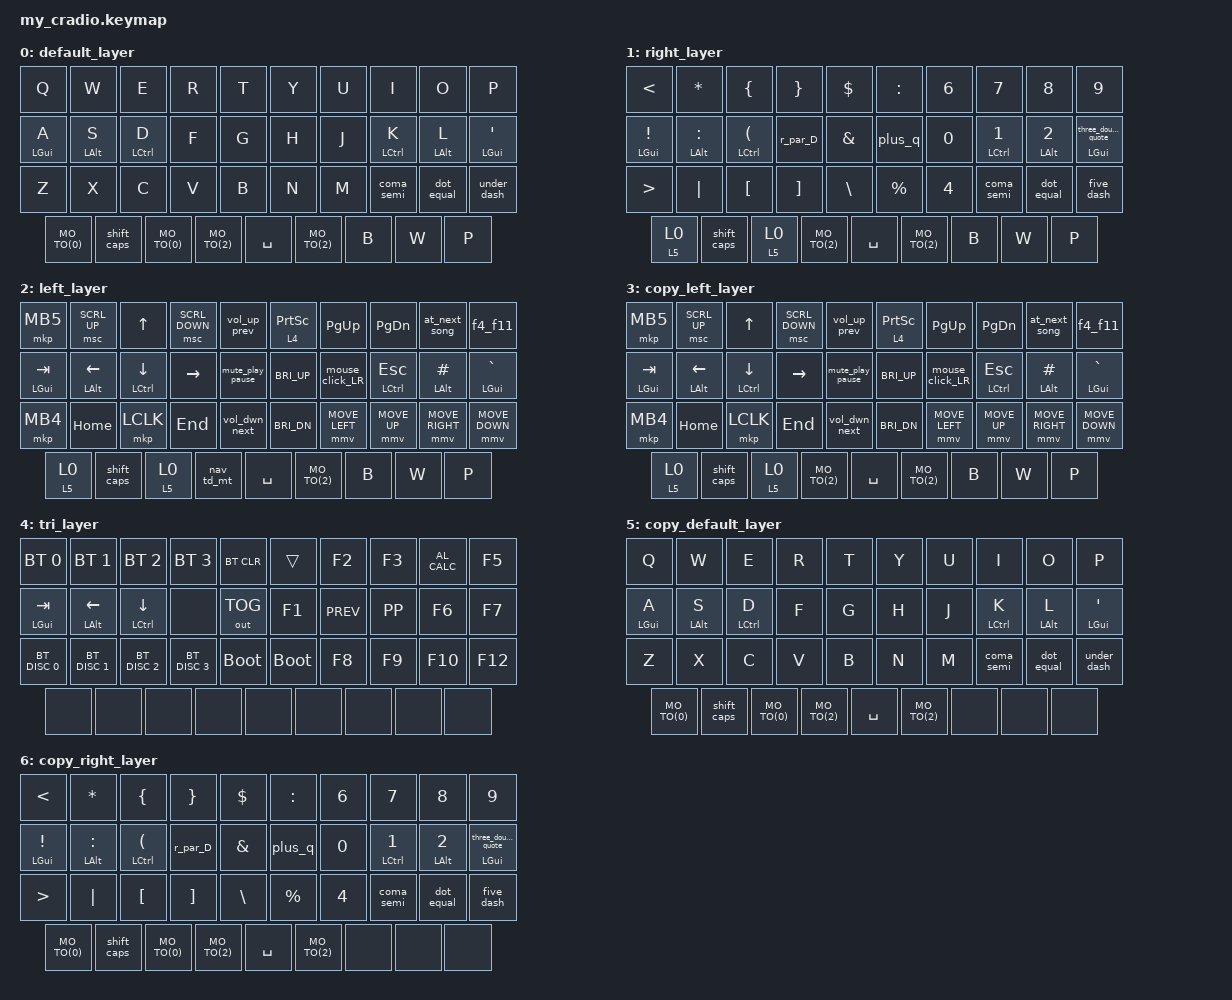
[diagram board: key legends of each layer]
// Copyright (c) 2022 The ZMK Contributors
// SPDX-License-Identifier: MIT

#define ZMK_POINTING_DEFAULT_MOVE_VAL 1500  // default: 600
#define ZMK_POINTING_DEFAULT_SCRL_VAL 200    // default: 10

#include <behaviors.dtsi>
#include <input/processors.dtsi>
#include <zephyr/dt-bindings/input/input-event-codes.h>
#include <dt-bindings/zmk/keys.h>
#include <dt-bindings/zmk/bt.h>
//#include <dt-bindings/zmk/mouse.h>
#include <dt-bindings/zmk/outputs.h>
#include <dt-bindings/zmk/pointing.h>


#define MO_TO(layer) &mo_to layer layer   // Macro to apply momentary-layer-on-hold/toggle-layer-on-tap to a specific layer

&mmv {
  acceleration-exponent = <1>;          // 1
  time-to-max-speed-ms = <700>;         // 300
  delay-ms = <0>;                       // 0
};

&msc {
  acceleration-exponent = <0>;          // 0
  time-to-max-speed-ms = <0>;         // 300
  delay-ms = <0>;                       // 0
};

&mmv_input_listener {
  fast {
    layers = <3>;
    input-processors = <&zip_xy_scaler 7 2>;
  };
};

&msc_input_listener {
  fast {
    layers = <3>;
    input-processors = <&zip_scroll_scaler 7 1>;
  };
};

/ {
    macros {
        fast_scrl_up: fast_scrl_up {
            compatible = "zmk,behavior-macro";
            #binding-cells = <0>;
            wait-ms = <0>;
            tap-ms = <0>;
            bindings
                = <&macro_press &mo 3>
                , <&macro_press &msc SCRL_UP>
                , <&macro_pause_for_release>
                , <&macro_release &msc SCRL_UP>
                , <&macro_release &mo 3>;
        };
        
        fast_scrl_dn: fast_scrl_dn {
            compatible = "zmk,behavior-macro";
            #binding-cells = <0>;
            wait-ms = <0>;
            tap-ms = <0>;
            bindings
                = <&macro_press &mo 3>
                , <&macro_press &msc SCRL_DOWN>
                , <&macro_pause_for_release>
                , <&macro_release &msc SCRL_DOWN>
                , <&macro_release &mo 3>;
        };
    };

    combos {
        compatible = "zmk,combos";
        combo_undo {
            timeout-ms = <30>;
            key-positions = <20 21>;
            bindings = <&kp LC(Z)>;
            require-prior-idle-ms = <50>;
        };
        combo_copy {
            timeout-ms = <30>;
            key-positions = <21 22>;
            bindings = <&kp LC(C)>;
            require-prior-idle-ms = <50>;
        };
        combo_shift_copy {
            timeout-ms = <30>;
            key-positions = <21 22 31>;
            bindings = <&kp LS(LC(C))>;
            require-prior-idle-ms = <50>;
        };
        combo_paste {
            timeout-ms = <30>;
            key-positions = <22 23>;
            bindings = <&kp LC(V)>;
            require-prior-idle-ms = <50>;
        };
        combo_shift_paste {
            timeout-ms = <30>;
            key-positions = <22 23 31>;
            bindings = <&kp LS(LC(V))>;
            require-prior-idle-ms = <50>;
        };
        combo_cut {
            timeout-ms = <30>;
            key-positions = <23 24>;
            bindings = <&kp LC(X)>;
            require-prior-idle-ms = <50>;
        };
        combo_backspace {
            timeout-ms = <30>;
            key-positions = <12 13>;
            bindings = <&kp BSPC>;
            require-prior-idle-ms = <50>;
        };
        combo_backspace_2 {
            timeout-ms = <30>;
            key-positions = <15 16>;
            bindings = <&kp BSPC>;
            require-prior-idle-ms = <50>;
        };
        combo_delete {
            timeout-ms = <30>;
            key-positions = <16 17>;
            bindings = <&kp DEL>;
            require-prior-idle-ms = <50>;
        };
        combo_delete_2 {
            timeout-ms = <30>;
            key-positions = <21 23>;
            bindings = <&kp DEL>;
            require-prior-idle-ms = <50>;
        };
        combo_enter {
            timeout-ms = <30>;
            key-positions = <17 18>;
            bindings = <&kp ENTER>;
            require-prior-idle-ms = <100>;
        };
        combo_enter_2 {
            timeout-ms = <30>;
            key-positions = <21 22 23>;
            bindings = <&kp ENTER>;
            require-prior-idle-ms = <50>;
        };
        combo_shift_enter {
            timeout-ms = <60>;
            key-positions = <17 18 31>;
            bindings = <&kp LS(ENTER)>;
            require-prior-idle-ms = <50>;
        };
        combo_shift_enter_2 {
            timeout-ms = <30>;
            key-positions = <21 22 23 31>;
            bindings = <&kp LS(ENTER)>;
            require-prior-idle-ms = <50>;
        };
        combo_space_left {
            timeout-ms = <30>;
            key-positions = <11 12 13>;
            bindings = <&kp SPACE>;
            require-prior-idle-ms = <50>;
        };
        combo_slash {
            timeout-ms = <30>;
            key-positions = <18 19>;
            bindings = <&kp SLASH>;
            require-prior-idle-ms = <50>;
        };
        // Needed in case I press shift too fast.
        combo_question {
            timeout-ms = <60>;
            key-positions = <18 19 31>;
            bindings = <&kp LS(SLASH)>;
            require-prior-idle-ms = <50>;
        };
        // First layer right hand
        combo_first_layer {
            timeout-ms = <30>;
            key-positions = <16 25>;
            bindings = <MO_TO(0)>;
            require-prior-idle-ms = <50>;
        };
        // Second layer left hand, nav layer
        combo_second_layer_2 {
            timeout-ms = <30>;
            key-positions = <11 13>;
            bindings = <MO_TO(2)>;
            require-prior-idle-ms = <50>;
        };


        // Third layer for numbers and symbols
        combo_third_layer {
            timeout-ms = <30>;
            key-positions = <32 33>;
            bindings = <&mo_to 6 1>;
        };
        combo_third_layer_broken_left_thumb {
            timeout-ms = <30>;
            key-positions = <30 33>;
            bindings = <&mo_to 6 1>;
        };
        combo_third_layer_2 {
            timeout-ms = <30>;
            key-positions = <11 12>;
            bindings = <&mo_to 6 1>;
        };
        combo_third_layer_3 {
            timeout-ms = <30>;
            key-positions = <16 18>;
            bindings = <&mo_to 6 1>;
        };
        combo_fast_scroll_up {
            timeout-ms = <30>;
            key-positions = <1 2>; // Position 1 is SCRL_UP, Position 2 is UP
            layers = <2>;          // Restricts this combo to only activate on layer 2 (left_layer)
            bindings = <&fast_scrl_up>;    // Momentarily activates layer 3 while held
            require-prior-idle-ms = <50>;
        };
        combo_fast_scroll_dn {
            timeout-ms = <30>;
            key-positions = <2 3>; // Position 1 is SCRL_UP, Position 2 is UP
            layers = <2>;          // Restricts this combo to only activate on layer 2 (left_layer)
            bindings = <&fast_scrl_dn>;    // Momentarily activates layer 3 while held
            require-prior-idle-ms = <50>;
        };
    };


    behaviors {
        // for home row mods
        ht: hold_tap {
            compatible = "zmk,behavior-hold-tap";
            #binding-cells = <2>;
            flavor = "tap-preferred";
            tapping-term-ms = <270>;
            quick-tap-ms = <250>;
            require-prior-idle-ms = <100>;
            bindings = <&kp>, <&kp>;
        };
        // momentary or toggle layer switch
        mo_to: behavior_mo_to {
            compatible = "zmk,behavior-hold-tap";
            #binding-cells = <2>;
            flavor = "hold-preferred";
            tapping-term-ms = <200>;
            bindings = <&mo>, <&to>;
        };

        nav_td_mt: tap_dance_mod_tap {
            compatible = "zmk,behavior-tap-dance";
            #binding-cells = <0>;
            tapping-term-ms = <700>;
            bindings = <&mo 3>, <&to 3>;
        };

        shift_caps: tap_dance_0 {
            compatible = "zmk,behavior-tap-dance";
            #binding-cells = <0>;
            tapping-term-ms = <240>;
            bindings = <&kp LSHIFT>, <&kp CAPS>;
        };

        coma_semi: coma_semi {
            compatible = "zmk,behavior-mod-morph";
            #binding-cells = <0>;
            bindings = <&kp COMMA>, <&kp SEMI>;
            mods = <(MOD_LSFT)>;
        };
        dot_equal: dot_equal {
            compatible = "zmk,behavior-mod-morph";
            #binding-cells = <0>;
            bindings = <&kp DOT>, <&kp EQUAL>;
            mods = <(MOD_LSFT)>;
        };
        under_dash: under_dash {
            compatible = "zmk,behavior-mod-morph";
            #binding-cells = <0>;
            bindings = <&kp UNDER>, <&kp MINUS>;
            mods = <(MOD_LSFT)>;
        };
        five_dash: five_dash {
            compatible = "zmk,behavior-mod-morph";
            #binding-cells = <0>;
            bindings = <&kp N5>, <&kp MINUS>;
            mods = <(MOD_LSFT)>;
        };


        three_double_quote: three_double_quote {
            compatible = "zmk,behavior-mod-morph";
            #binding-cells = <0>;
            bindings = <&kp N3>, <&kp DQT>;
            mods = <(MOD_LSFT)>;
        };
        
        hta: hta {
            compatible = "zmk,behavior-hold-tap";
            #binding-cells = <2>;
            flavor = "tap-preferred";
            tapping-term-ms = <270>;
            quick-tap-ms = <250>;
            require-prior-idle-ms = <100>;
            bindings = <&kp>, <&three_double_quote>;
        };


        plus_q: plus_q {
            compatible = "zmk,behavior-mod-morph";
            #binding-cells = <0>;
            bindings = <&kp PLUS>, <&kp LS(Q)>;
            mods = <(MOD_LSFT)>;
        };
        r_par_D: r_par_D {
            compatible = "zmk,behavior-mod-morph";
            #binding-cells = <0>;
            bindings = <&kp RPAR>, <&kp LS(D)>;
            mods = <(MOD_LSFT)>;
        };

        vol_up_prev: vol_up_prev {
            compatible = "zmk,behavior-mod-morph";
            #binding-cells = <0>;
            bindings = <&kp C_VOL_UP>, <&kp C_PREV>;
            mods = <(MOD_LSFT)>;
        };
        vol_dwn_next: vol_dwn_next {
            compatible = "zmk,behavior-mod-morph";
            #binding-cells = <0>;
            bindings = <&kp C_VOL_DN>, <&kp C_NEXT>;
            mods = <(MOD_LSFT)>;
        };
        at_next_song: at_next_song {
            compatible = "zmk,behavior-mod-morph";
            #binding-cells = <0>;
            bindings = <&kp AT>, <&kp K_NEXT>;
            mods = <(MOD_LSFT)>;
        };
        mute_play_pause: mute_play_pause {
            compatible = "zmk,behavior-mod-morph";
            #binding-cells = <0>;
            bindings = <&kp C_MUTE>, <&kp C_PP>;
            mods = <(MOD_LSFT)>;
        };
        f4_f11: f4_f11 {
            compatible = "zmk,behavior-mod-morph";
            #binding-cells = <0>;
            bindings = <&kp F4>, <&kp F11>;
            mods = <(MOD_LSFT)>;
        };
        f20_f21: f20_f21 {
            compatible = "zmk,behavior-mod-morph";
            #binding-cells = <0>;
            bindings = <&kp LS(F21)>, <&kp LS(F22)>;
            mods = <(MOD_LSFT)>;
        };
        mouse_click_LR: mouse_click_LR {
            compatible = "zmk,behavior-mod-morph";
            #binding-cells = <0>;
            bindings = <&mkp LCLK>, <&mkp RCLK>;
            mods = <(MOD_LSFT)>;
        };
    };


    keymap {
        compatible = "zmk,keymap";
        default_layer {
            bindings = <
        //╭──────────┬──────────┬──────────┬──────────┬──────────╮   ╭──────────┬──────────┬──────────┬──────────┬──────────╮
        //│  Q       │  W       │  E       │  R       │  T       │   │  Y       │  U       │  I       │  O       │  P       │
            &kp Q      &kp W      &kp E      &kp R      &kp T          &kp Y      &kp U      &kp I      &kp O      &kp P
        //├──────────┼──────────┼──────────┼──────────┼──────────┤   ├──────────┼──────────┼──────────┼──────────┼──────────┤
        //│  A       │  S       │  D       │  F       │  G       │   │  H       │  J       │  K       │  L       │  '  "    │
          &ht LGUI A  &ht LALT S  &ht LCTRL D   &kp F      &kp G          &kp H     &kp J  &ht LCTRL K  &ht LALT L   &ht LGUI SQT 
        //├──────────┼──────────┼──────────┼──────────┼──────────┤   ├──────────┼──────────┼──────────┼──────────┼──────────┤
        //│  Z       │  X       │  C       │  V       │  B       │   │  N       │  M       │ , ;      │ . =      │ _  -  /  │
            &kp Z      &kp X      &kp C      &kp V      &kp B          &kp N      &kp M    &coma_semi  &dot_equal    &under_dash 
        //╰──────────┴──────────┴──────────┼──────────┼──────────┤   ├──────────┼──────────┼──────────┴──────────┴──────────╯
                                 MO_TO(0)   &shift_caps  MO_TO(0)     MO_TO(2)   &kp SPACE   MO_TO(2)       &kp B   &kp W   &kp P
        //                                 ╰──────────┴──────────╯   ╰──────────┴──────────╯
            >;
        };

        right_layer {
            bindings = <
        //╭──────────┬──────────┬──────────┬──────────┬──────────╮   ╭──────────┬──────────┬──────────┬──────────┬──────────╮
        //│  <       │    *     │	  {    │     }    │     $    │   │   :      │   6  ^   │    7     │   8      │    9     │
            &kp LT     &kp STAR    &kp LBRC   &kp RBRC  &kp DLLR      &kp COLON   &kp N6    &kp N7      &kp N8    &kp N9   
        //├──────────┼──────────┼──────────┼──────────┼──────────┤   ├──────────┼──────────┼──────────┼──────────┼──────────┤
        //│   !      │ 	 :      │  (       │   )   D  │   &      │   │   +   Q  │   0      │  1       │   2      │  3       │
&ht LGUI EXCL  &ht LALT COLON  &ht LCTRL LPAR  &r_par_D  &kp AMPS     &plus_q   &kp N0  &ht LCTRL N1  &ht LALT N2  &hta LGUI 0
        //├──────────┼──────────┼──────────┼──────────┼──────────┤   ├──────────┼──────────┼──────────┼──────────┼──────────┤
        //│    >     │  |       │  [       │  ]       │  \       │   │    %     │    4     │   , ;    │   . =    │   5  -   │
           &kp GT    &kp PIPE    &kp LBKT  &kp RBKT    &kp BSLH        &kp PRCNT    &kp N4   &coma_semi  &dot_equal   &five_dash
        //╰──────────┴──────────┴──────────┼──────────┼──────────┤   ├──────────┼──────────┼──────────┴──────────┴──────────╯
                               &mo_to 5 0   &shift_caps  &mo_to 5 0     MO_TO(2)   &kp SPACE   MO_TO(2)         &kp B   &kp W   &kp P
        //                                 ╰──────────┴──────────╯   ╰──────────┴──────────╯
            >;
        };

        left_layer {
            bindings = <
        //╭──────────┬──────────┬──────────┬──────────┬──────────╮   ╭──────────┬──────────┬──────────┬──────────┬──────────╮
        //│ MousBtn5 │  ScrlUp  │    UP    │ ScrlDwn  │ VolUpPrev│   │Scrn/UpLyr│   PgUp   │  PgDwn   │  @  Next │ F4  F11  │
     &mkp MB5  &msc SCRL_UP  &kp UP  &msc SCRL_DOWN  &vol_up_prev    &lt 4 PSCRN  &kp PG_UP  &kp PG_DN  &at_next_song  &f4_f11 
        //├──────────┼──────────┼──────────┼──────────┼──────────┤   ├──────────┼──────────┼──────────┼──────────┼──────────┤
        //│  TAB     │  Left    │  Down    │  RIGHT   │ mute/Play│   |BrightUp  |Mouse Clck│    ESC   │    #     │   `  ~   │
&ht LGUI TAB  &ht LALT LEFT  &ht LCTRL DOWN  &kp RIGHT  &mute_play_pause  &kp C_BRI_UP  &mouse_click_LR  &ht LCTRL ESC  &ht LALT HASH   &ht LGUI GRAVE
        //├──────────┼──────────┼──────────┼──────────┼──────────┤   ├──────────┼──────────┼──────────┼──────────┼──────────┤
        //│ MousBtn4 │   Home   │Mouse Clck│   End    |VolDwnNext│   │ BrightDwn│Mouse Left| Mouse Up │MouseRight|Mouse Down|
            &mkp MB4  &kp HOME  &mkp LCLK  &kp END  &vol_dwn_next    &kp C_BRI_DN  &mmv MOVE_LEFT  &mmv MOVE_UP  &mmv MOVE_RIGHT  &mmv MOVE_DOWN
        //╰──────────┴──────────┴──────────┼──────────┼──────────┤   ├──────────┼──────────┼──────────┴──────────┴──────────╯
                            &mo_to 5 0    &shift_caps  &mo_to 5 0     &nav_td_mt   &kp SPACE   MO_TO(2)         &kp B   &kp W   &kp P
        //                                 ╰──────────┴──────────╯   ╰──────────┴──────────╯
            >;
        };
        
        copy_left_layer {
            bindings = <
        //╭──────────┬──────────┬──────────┬──────────┬──────────╮   ╭──────────┬──────────┬──────────┬──────────┬──────────╮
        //│ MousBtn5 │  ScrlUp  │    UP    │ ScrlDwn  │ VolUpPrev│   │Scrn/UpLyr│   PgUp   │  PgDwn   │  @  Next │ F4  F11  │
     &mkp MB5  &msc SCRL_UP  &kp UP  &msc SCRL_DOWN  &vol_up_prev    &lt 4 PSCRN  &kp PG_UP  &kp PG_DN  &at_next_song  &f4_f11 
        //├──────────┼──────────┼──────────┼──────────┼──────────┤   ├──────────┼──────────┼──────────┼──────────┼──────────┤
        //│  TAB     │  Left    │  Down    │  RIGHT   │ mute/Play│   |BrightUp  |Mouse Clck│    ESC   │    #     │   `  ~   │
&ht LGUI TAB  &ht LALT LEFT  &ht LCTRL DOWN  &kp RIGHT  &mute_play_pause  &kp C_BRI_UP  &mouse_click_LR  &ht LCTRL ESC  &ht LALT HASH   &ht LGUI GRAVE
        //├──────────┼──────────┼──────────┼──────────┼──────────┤   ├──────────┼──────────┼──────────┼──────────┼──────────┤
        //│ MousBtn4 │   Home   │Mouse Clck│   End    |VolDwnNext│   │ BrightDwn│Mouse Left| Mouse Up │MouseRight|Mouse Down|
            &mkp MB4  &kp HOME  &mkp LCLK  &kp END  &vol_dwn_next    &kp C_BRI_DN  &mmv MOVE_LEFT  &mmv MOVE_UP  &mmv MOVE_RIGHT  &mmv MOVE_DOWN
        //╰──────────┴──────────┴──────────┼──────────┼──────────┤   ├──────────┼──────────┼──────────┴──────────┴──────────╯
                            &mo_to 5 0    &shift_caps  &mo_to 5 0      MO_TO(2)   &kp SPACE   MO_TO(2)         &kp B   &kp W   &kp P
        //                                 ╰──────────┴──────────╯   ╰──────────┴──────────╯
            >;
        };

        tri_layer {
            bindings = <
        //╭──────────┬──────────┬──────────┬──────────┬──────────╮   ╭──────────┬──────────┬──────────┬──────────┬──────────╮
        //│  BT0     │  Bt1     │     BT2  │  BT3     | CLEAR BT │   │KeepUpLaye│   F2     │   F3     │Calculator│   F5     │
      &bt BT_SEL 0 &bt BT_SEL 1 &bt BT_SEL 2 &bt BT_SEL 3  &bt BT_CLR     &trans   &kp F2     &kp F3    &kp C_AL_CALC   &kp F5
        //├──────────┼──────────┼──────────┼──────────┼──────────┤   ├──────────┼──────────┼──────────┼──────────┼──────────┤
        //│          │          │          │          │USB BLE TG│   │   F1     │ Prev Song│Play Pause│   F6     │   F7     │
  &ht LGUI TAB  &ht LALT LEFT  &ht LCTRL DOWN  &none  &out OUT_TOG      &kp F1   &kp K_PREV  &kp K_PP   &kp F6   &kp F7  
        //├──────────┼──────────┼──────────┼──────────┼──────────┤   ├──────────┼──────────┼──────────┼──────────┼──────────┤
        //│ BtDiscon0| BtDiscon1│ BtDiscon2│ BtDiscon3│BOOTLOADER│   │BOOTLOADER│    F8    │   F9     │    F10   │   F12    │
 &bt BT_DISC 0 &bt BT_DISC 1 &bt BT_DISC 2 &bt BT_DISC 3 &bootloader   &bootloader  &kp F8    &kp F9     &kp F10   &kp F12
        //╰──────────┴──────────┴──────────┼──────────┼──────────┤   ├──────────┼──────────┼──────────┴──────────┴──────────╯
                                    &none        &none     &none         &none     &none    &none   &none     &none    &none  
        //                                 ╰──────────┴──────────╯   ╰──────────┴──────────╯
            >;
        };
        
        copy_default_layer {
            bindings = <
        //╭──────────┬──────────┬──────────┬──────────┬──────────╮   ╭──────────┬──────────┬──────────┬──────────┬──────────╮
        //│  Q       │  W       │  E       │  R       │  T       │   │  Y       │  U       │  I       │  O       │  P       │
            &kp Q      &kp W      &kp E      &kp R      &kp T          &kp Y      &kp U      &kp I      &kp O      &kp P
        //├──────────┼──────────┼──────────┼──────────┼──────────┤   ├──────────┼──────────┼──────────┼──────────┼──────────┤
        //│  A       │  S       │  D       │  F       │  G       │   │  H       │  J       │  K       │  L       │  '  "    │
          &ht LGUI A  &ht LALT S  &ht LCTRL D   &kp F      &kp G          &kp H     &kp J  &ht LCTRL K  &ht LALT L   &ht LGUI SQT 
        //├──────────┼──────────┼──────────┼──────────┼──────────┤   ├──────────┼──────────┼──────────┼──────────┼──────────┤
        //│  Z       │  X       │  C       │  V       │  B       │   │  N       │  M       │ , ;      │ . =      │ _  -  /  │
            &kp Z      &kp X      &kp C      &kp V      &kp B          &kp N      &kp M    &coma_semi  &dot_equal    &under_dash 
        //╰──────────┴──────────┴──────────┼──────────┼──────────┤   ├──────────┼──────────┼──────────┴──────────┴──────────╯
        // ********************* IF YOU UPDATE THE KEYMAP, DON'T CHANGE THE THUMBS. ************************
                                 MO_TO(0)   &shift_caps  MO_TO(0)     MO_TO(2)   &kp SPACE   MO_TO(2)   &none     &none    &none  
        //                                 ╰──────────┴──────────╯   ╰──────────┴──────────╯
            >;
        };
        
        copy_right_layer {
            bindings = <
        //╭──────────┬──────────┬──────────┬──────────┬──────────╮   ╭──────────┬──────────┬──────────┬──────────┬──────────╮
        //│  <       │    *     │	  {    │     }    │     $    │   │    :     │   6  ^   │    7     │   8      │    9     │
            &kp LT     &kp STAR    &kp LBRC   &kp RBRC  &kp DLLR      &kp COLON   &kp N6    &kp N7      &kp N8    &kp N9   
        //├──────────┼──────────┼──────────┼──────────┼──────────┤   ├──────────┼──────────┼──────────┼──────────┼──────────┤
        //│   !      │ 	 :      │  (       │   )   D  │   &      │   │   +   Q  │   0      │  1       │   2      │  3       │
&ht LGUI EXCL  &ht LALT COLON  &ht LCTRL LPAR  &r_par_D  &kp AMPS     &plus_q   &kp N0  &ht LCTRL N1  &ht LALT N2  &hta LGUI 0
        //├──────────┼──────────┼──────────┼──────────┼──────────┤   ├──────────┼──────────┼──────────┼──────────┼──────────┤
        //│    >     │  |       │  [       │  ]       │  \       │   │    %     │    4     │   , ;    │   . =    │   5  -   │
           &kp GT    &kp PIPE    &kp LBKT  &kp RBKT    &kp BSLH         &kp PRCNT   &kp N4   &coma_semi  &dot_equal   &five_dash
        //╰──────────┴──────────┴──────────┼──────────┼──────────┤   ├──────────┼──────────┼──────────┴──────────┴──────────╯
        // ********************* IF YOU UPDATE THE KEYMAP, DON'T CHANGE THE THUMBS. ************************
                                 MO_TO(0)   &shift_caps  MO_TO(0)     MO_TO(2)   &kp SPACE   MO_TO(2)  &none     &none    &none  
        //                                 ╰──────────┴──────────╯   ╰──────────┴──────────╯
            >;
        };
    };
};

